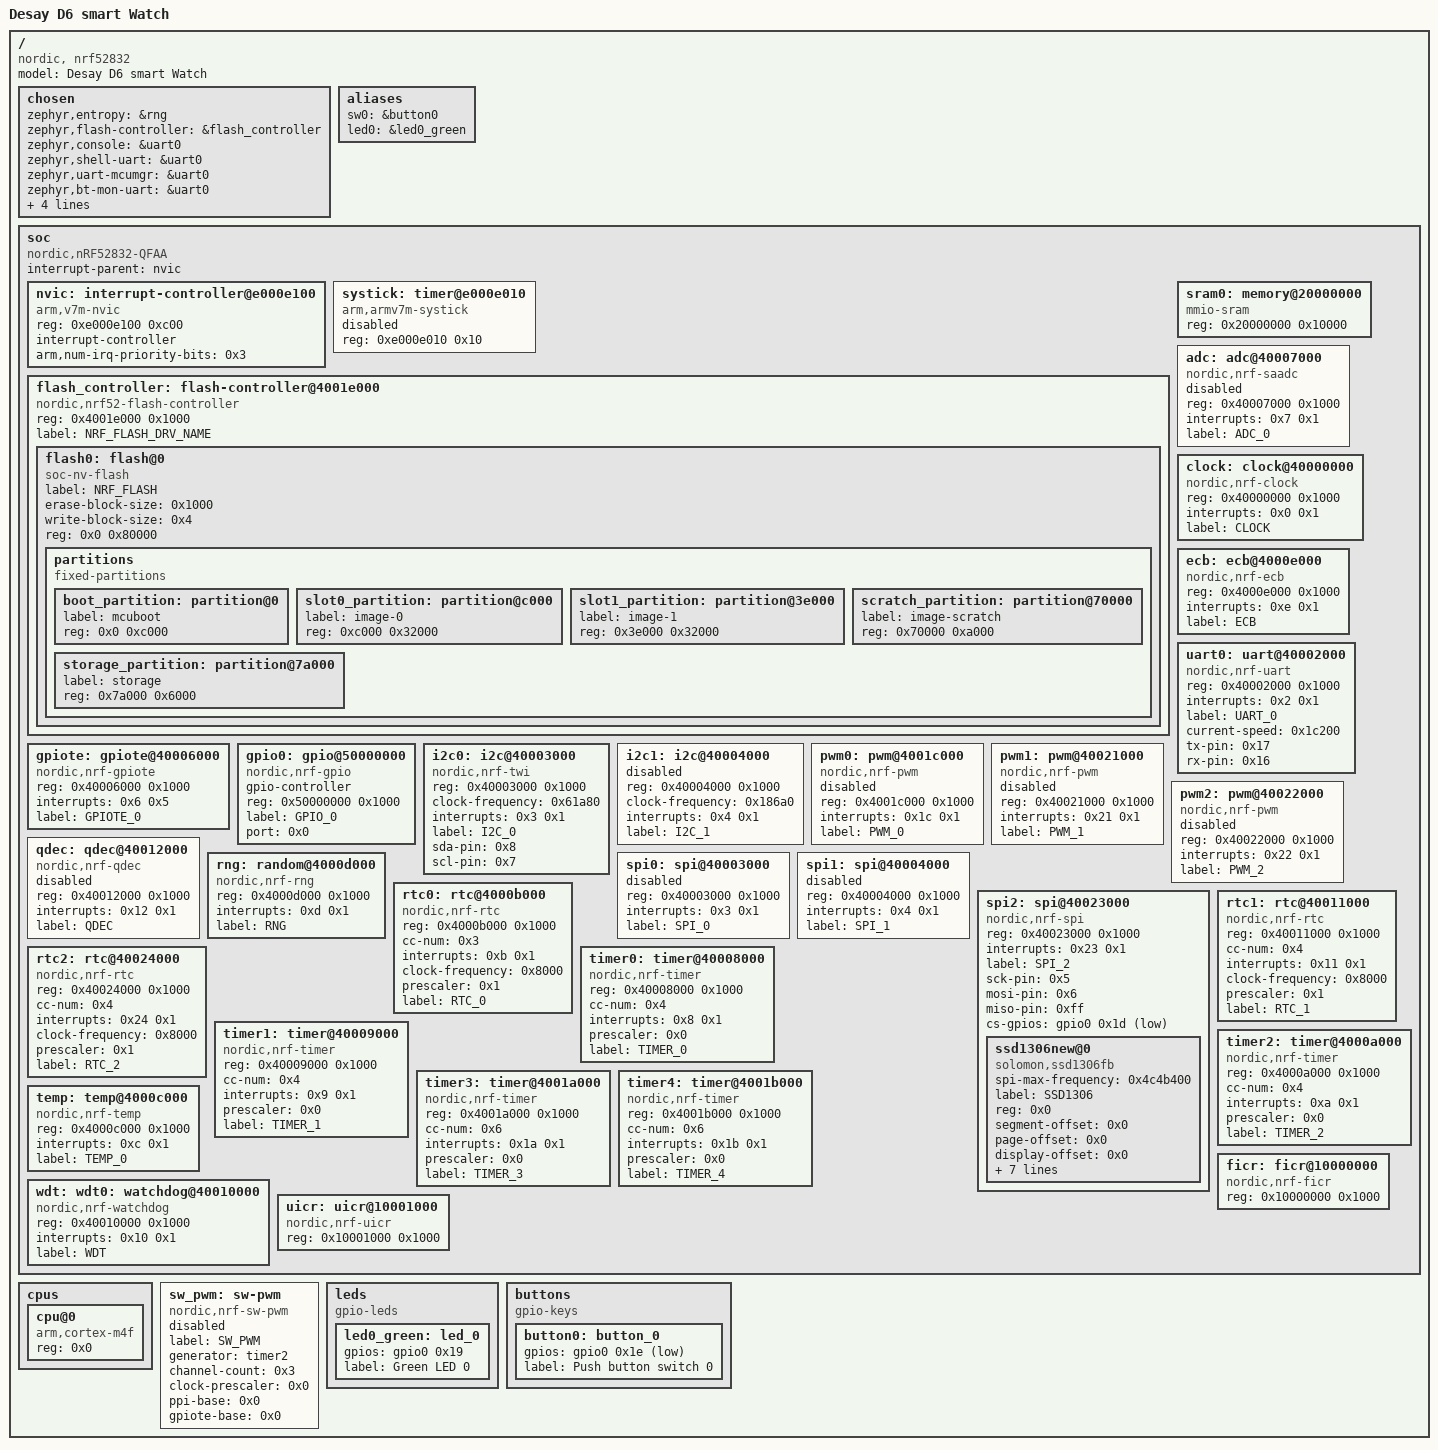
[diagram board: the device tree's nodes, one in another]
/dts-v1/;

/ {
	#address-cells = < 0x1 >;
	#size-cells = < 0x1 >;
	model = "Desay D6 smart Watch";
	compatible = "nordic, nrf52832";
	chosen {
		zephyr,entropy = &rng;
		zephyr,flash-controller = &flash_controller;
		zephyr,console = &uart0;
		zephyr,shell-uart = &uart0;
		zephyr,uart-mcumgr = &uart0;
		zephyr,bt-mon-uart = &uart0;
		zephyr,bt-c2h-uart = &uart0;
		zephyr,sram = &sram0;
		zephyr,flash = &flash0;
		zephyr,code-partition = &slot0_partition;
	};
	aliases {
		sw0 = &button0;
		led0 = &led0_green;
	};
	soc {
		#address-cells = < 0x1 >;
		#size-cells = < 0x1 >;
		compatible = "nordic,nRF52832-QFAA", "nordic,nRF52832", "nordic,nRF52", "simple-bus";
		interrupt-parent = < &nvic >;
		ranges;
		nvic: interrupt-controller@e000e100 {
			compatible = "arm,v7m-nvic";
			reg = < 0xe000e100 0xc00 >;
			interrupt-controller;
			#interrupt-cells = < 0x2 >;
			arm,num-irq-priority-bits = < 0x3 >;
			phandle = < 0x1 >;
		};
		systick: timer@e000e010 {
			compatible = "arm,armv7m-systick";
			reg = < 0xe000e010 0x10 >;
			status = "disabled";
		};
		flash_controller: flash-controller@4001e000 {
			compatible = "nordic,nrf52-flash-controller";
			reg = < 0x4001e000 0x1000 >;
			#address-cells = < 0x1 >;
			#size-cells = < 0x1 >;
			label = "NRF_FLASH_DRV_NAME";
			flash0: flash@0 {
				compatible = "soc-nv-flash";
				label = "NRF_FLASH";
				erase-block-size = < 0x1000 >;
				write-block-size = < 0x4 >;
				reg = < 0x0 0x80000 >;
				partitions {
					compatible = "fixed-partitions";
					#address-cells = < 0x1 >;
					#size-cells = < 0x1 >;
					boot_partition: partition@0 {
						label = "mcuboot";
						reg = < 0x0 0xc000 >;
					};
					slot0_partition: partition@c000 {
						label = "image-0";
						reg = < 0xc000 0x32000 >;
					};
					slot1_partition: partition@3e000 {
						label = "image-1";
						reg = < 0x3e000 0x32000 >;
					};
					scratch_partition: partition@70000 {
						label = "image-scratch";
						reg = < 0x70000 0xa000 >;
					};
					storage_partition: partition@7a000 {
						label = "storage";
						reg = < 0x7a000 0x6000 >;
					};
				};
			};
		};
		sram0: memory@20000000 {
			compatible = "mmio-sram";
			reg = < 0x20000000 0x10000 >;
		};
		adc: adc@40007000 {
			compatible = "nordic,nrf-saadc";
			reg = < 0x40007000 0x1000 >;
			interrupts = < 0x7 0x1 >;
			status = "disabled";
			label = "ADC_0";
			#io-channel-cells = < 0x1 >;
		};
		clock: clock@40000000 {
			compatible = "nordic,nrf-clock";
			reg = < 0x40000000 0x1000 >;
			interrupts = < 0x0 0x1 >;
			status = "okay";
			label = "CLOCK";
		};
		ecb: ecb@4000e000 {
			compatible = "nordic,nrf-ecb";
			reg = < 0x4000e000 0x1000 >;
			interrupts = < 0xe 0x1 >;
			status = "okay";
			label = "ECB";
		};
		uart0: uart@40002000 {
			reg = < 0x40002000 0x1000 >;
			interrupts = < 0x2 0x1 >;
			status = "okay";
			label = "UART_0";
			compatible = "nordic,nrf-uart";
			current-speed = < 0x1c200 >;
			tx-pin = < 0x17 >;
			rx-pin = < 0x16 >;
		};
		gpiote: gpiote@40006000 {
			compatible = "nordic,nrf-gpiote";
			reg = < 0x40006000 0x1000 >;
			interrupts = < 0x6 0x5 >;
			status = "okay";
			label = "GPIOTE_0";
		};
		gpio0: gpio@50000000 {
			compatible = "nordic,nrf-gpio";
			gpio-controller;
			reg = < 0x50000000 0x1000 >;
			#gpio-cells = < 0x2 >;
			label = "GPIO_0";
			status = "okay";
			port = < 0x0 >;
			phandle = < 0x2 >;
		};
		i2c0: i2c@40003000 {
			#address-cells = < 0x1 >;
			#size-cells = < 0x0 >;
			reg = < 0x40003000 0x1000 >;
			clock-frequency = < 0x61a80 >;
			interrupts = < 0x3 0x1 >;
			status = "okay";
			label = "I2C_0";
			compatible = "nordic,nrf-twi";
			sda-pin = < 0x8 >;
			scl-pin = < 0x7 >;
		};
		i2c1: i2c@40004000 {
			#address-cells = < 0x1 >;
			#size-cells = < 0x0 >;
			reg = < 0x40004000 0x1000 >;
			clock-frequency = < 0x186a0 >;
			interrupts = < 0x4 0x1 >;
			status = "disabled";
			label = "I2C_1";
		};
		pwm0: pwm@4001c000 {
			compatible = "nordic,nrf-pwm";
			reg = < 0x4001c000 0x1000 >;
			interrupts = < 0x1c 0x1 >;
			status = "disabled";
			label = "PWM_0";
			#pwm-cells = < 0x1 >;
		};
		pwm1: pwm@40021000 {
			compatible = "nordic,nrf-pwm";
			reg = < 0x40021000 0x1000 >;
			interrupts = < 0x21 0x1 >;
			status = "disabled";
			label = "PWM_1";
			#pwm-cells = < 0x1 >;
		};
		pwm2: pwm@40022000 {
			compatible = "nordic,nrf-pwm";
			reg = < 0x40022000 0x1000 >;
			interrupts = < 0x22 0x1 >;
			status = "disabled";
			label = "PWM_2";
			#pwm-cells = < 0x1 >;
		};
		qdec: qdec@40012000 {
			compatible = "nordic,nrf-qdec";
			reg = < 0x40012000 0x1000 >;
			interrupts = < 0x12 0x1 >;
			status = "disabled";
			label = "QDEC";
		};
		rng: random@4000d000 {
			compatible = "nordic,nrf-rng";
			reg = < 0x4000d000 0x1000 >;
			interrupts = < 0xd 0x1 >;
			status = "okay";
			label = "RNG";
		};
		spi0: spi@40003000 {
			#address-cells = < 0x1 >;
			#size-cells = < 0x0 >;
			reg = < 0x40003000 0x1000 >;
			interrupts = < 0x3 0x1 >;
			status = "disabled";
			label = "SPI_0";
		};
		spi1: spi@40004000 {
			#address-cells = < 0x1 >;
			#size-cells = < 0x0 >;
			reg = < 0x40004000 0x1000 >;
			interrupts = < 0x4 0x1 >;
			status = "disabled";
			label = "SPI_1";
		};
		spi2: spi@40023000 {
			#address-cells = < 0x1 >;
			#size-cells = < 0x0 >;
			reg = < 0x40023000 0x1000 >;
			interrupts = < 0x23 0x1 >;
			status = "okay";
			label = "SPI_2";
			compatible = "nordic,nrf-spi";
			sck-pin = < 0x5 >;
			mosi-pin = < 0x6 >;
			miso-pin = < 0xff >;
			cs-gpios = < &gpio0 0x1d 0x1 >;
			ssd1306new@0 {
				compatible = "solomon,ssd1306fb";
				spi-max-frequency = < 0x4c4b400 >;
				label = "SSD1306";
				reg = < 0x0 >;
				segment-offset = < 0x0 >;
				page-offset = < 0x0 >;
				display-offset = < 0x0 >;
				multiplex-ratio = < 0x1f >;
				height = < 0x20 >;
				width = < 0x80 >;
				segment-remap;
				prechargep = < 0xf1 >;
				reset-gpios = < &gpio0 0x4 0x0 >;
				data_cmd-gpios = < &gpio0 0x1c 0x0 >;
			};
		};
		rtc0: rtc@4000b000 {
			compatible = "nordic,nrf-rtc";
			reg = < 0x4000b000 0x1000 >;
			cc-num = < 0x3 >;
			interrupts = < 0xb 0x1 >;
			status = "okay";
			clock-frequency = < 0x8000 >;
			prescaler = < 0x1 >;
			label = "RTC_0";
		};
		rtc1: rtc@40011000 {
			compatible = "nordic,nrf-rtc";
			reg = < 0x40011000 0x1000 >;
			cc-num = < 0x4 >;
			interrupts = < 0x11 0x1 >;
			status = "okay";
			clock-frequency = < 0x8000 >;
			prescaler = < 0x1 >;
			label = "RTC_1";
		};
		rtc2: rtc@40024000 {
			compatible = "nordic,nrf-rtc";
			reg = < 0x40024000 0x1000 >;
			cc-num = < 0x4 >;
			interrupts = < 0x24 0x1 >;
			status = "okay";
			clock-frequency = < 0x8000 >;
			prescaler = < 0x1 >;
			label = "RTC_2";
		};
		timer0: timer@40008000 {
			compatible = "nordic,nrf-timer";
			status = "okay";
			reg = < 0x40008000 0x1000 >;
			cc-num = < 0x4 >;
			interrupts = < 0x8 0x1 >;
			prescaler = < 0x0 >;
			label = "TIMER_0";
		};
		timer1: timer@40009000 {
			compatible = "nordic,nrf-timer";
			status = "okay";
			reg = < 0x40009000 0x1000 >;
			cc-num = < 0x4 >;
			interrupts = < 0x9 0x1 >;
			prescaler = < 0x0 >;
			label = "TIMER_1";
		};
		timer2: timer@4000a000 {
			compatible = "nordic,nrf-timer";
			status = "okay";
			reg = < 0x4000a000 0x1000 >;
			cc-num = < 0x4 >;
			interrupts = < 0xa 0x1 >;
			prescaler = < 0x0 >;
			label = "TIMER_2";
			phandle = < 0x3 >;
		};
		timer3: timer@4001a000 {
			compatible = "nordic,nrf-timer";
			status = "okay";
			reg = < 0x4001a000 0x1000 >;
			cc-num = < 0x6 >;
			interrupts = < 0x1a 0x1 >;
			prescaler = < 0x0 >;
			label = "TIMER_3";
		};
		timer4: timer@4001b000 {
			compatible = "nordic,nrf-timer";
			status = "okay";
			reg = < 0x4001b000 0x1000 >;
			cc-num = < 0x6 >;
			interrupts = < 0x1b 0x1 >;
			prescaler = < 0x0 >;
			label = "TIMER_4";
		};
		temp: temp@4000c000 {
			compatible = "nordic,nrf-temp";
			reg = < 0x4000c000 0x1000 >;
			interrupts = < 0xc 0x1 >;
			status = "okay";
			label = "TEMP_0";
		};
		wdt: wdt0: watchdog@40010000 {
			compatible = "nordic,nrf-watchdog";
			reg = < 0x40010000 0x1000 >;
			interrupts = < 0x10 0x1 >;
			status = "okay";
			label = "WDT";
		};
		ficr: ficr@10000000 {
			compatible = "nordic,nrf-ficr";
			reg = < 0x10000000 0x1000 >;
			status = "okay";
		};
		uicr: uicr@10001000 {
			compatible = "nordic,nrf-uicr";
			reg = < 0x10001000 0x1000 >;
			status = "okay";
		};
	};
	cpus {
		#address-cells = < 0x1 >;
		#size-cells = < 0x0 >;
		cpu@0 {
			device_type = "cpu";
			compatible = "arm,cortex-m4f";
			reg = < 0x0 >;
		};
	};
	sw_pwm: sw-pwm {
		compatible = "nordic,nrf-sw-pwm";
		status = "disabled";
		label = "SW_PWM";
		generator = < &timer2 >;
		channel-count = < 0x3 >;
		clock-prescaler = < 0x0 >;
		ppi-base = < 0x0 >;
		gpiote-base = < 0x0 >;
		#pwm-cells = < 0x1 >;
	};
	leds {
		compatible = "gpio-leds";
		led0_green: led_0 {
			gpios = < &gpio0 0x19 0x0 >;
			label = "Green LED 0";
		};
	};
	buttons {
		compatible = "gpio-keys";
		button0: button_0 {
			gpios = < &gpio0 0x1e 0x11 >;
			label = "Push button switch 0";
		};
	};
};
